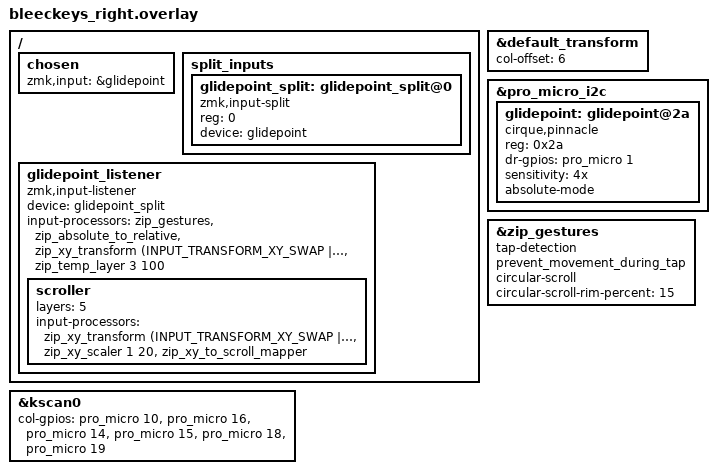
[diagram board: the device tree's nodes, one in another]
#include "bleeckeys.dtsi" // The shared dtsi file is included in the overlay
#include <dt-bindings/zmk/input_transform.h>
#include <input/processors.dtsi>
#include <dt-bindings/zmk/input_transform.h>
#include <behaviors/input_processor_gestures.dtsi>
#include <behaviors/input_processor_absolute_to_relative.dtsi>

&default_transform {
    col-offset = <6>;
};


/ {
    chosen {
        zmk,input = &glidepoint;
    };
};

// Label of the kscan node in the dtsi
&kscan0 {
    col-gpios
        = <&pro_micro 10 GPIO_ACTIVE_HIGH>
        , <&pro_micro 16 GPIO_ACTIVE_HIGH>
        , <&pro_micro 14 GPIO_ACTIVE_HIGH>
        , <&pro_micro 15 GPIO_ACTIVE_HIGH>
        , <&pro_micro 18 GPIO_ACTIVE_HIGH>
        , <&pro_micro 19 GPIO_ACTIVE_HIGH>
        ;
};

//&pinctrl {
//    i2c0_default {
//        group1 {
//            psels = <NRF_PSEL(TWIM_SDA, 0, 20)>,
//                <NRF_PSEL(TWIM_SCL, 0, 17)>;
//            bias-pull-up;
//        };
//    };
//    i2c0_sleep: i2c0_sleep {
//        group1 {
//            psels = <NRF_PSEL(TWIM_SDA, 0, 20)>,
//                <NRF_PSEL(TWIM_SCL, 0, 17)>;
//            low-power-enable;
//        };
//    };
//};
//
&pro_micro_i2c {
    status = "okay";
    glidepoint: glidepoint@2a {
        compatible = "cirque,pinnacle";
        status = "okay";
        reg = <0x2a>;
        dr-gpios = <&pro_micro 1 (GPIO_ACTIVE_HIGH)>;

        sensitivity = "4x";
        //sleep;
        absolute-mode;
    };
};

&glidepoint_split {
    device = <&glidepoint>;
};

&glidepoint_split {
    device = <&glidepoint>;
};

/ {
    split_inputs {
        #address-cells = <1>;
        #size-cells = <0>;

        glidepoint_split: glidepoint_split@0 {
            compatible = "zmk,input-split";
            reg = <0>;
        };
    };

    glidepoint_listener: glidepoint_listener {
        compatible = "zmk,input-listener";
        status = "okay";
        device = <&glidepoint_split>;
    };
};

&zip_gestures {
    tap-detection;
    prevent_movement_during_tap;

    circular-scroll;
    circular-scroll-rim-percent=<15>;
};

/ {
    glidepoint_listener {
        compatible = "zmk,input-listener";
        device = <&glidepoint_split>;
        
        input-processors = <
            &zip_gestures
            &zip_absolute_to_relative
            &zip_xy_transform (INPUT_TRANSFORM_XY_SWAP | INPUT_TRANSFORM_Y_INVERT)
            &zip_temp_layer 3 100
        >;
        scroller {
            layers = <5>;
            input-processors = <
                &zip_xy_transform (INPUT_TRANSFORM_XY_SWAP | INPUT_TRANSFORM_X_INVERT)
                &zip_xy_scaler 1 20
                &zip_xy_to_scroll_mapper
            >;
        };
    };
};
